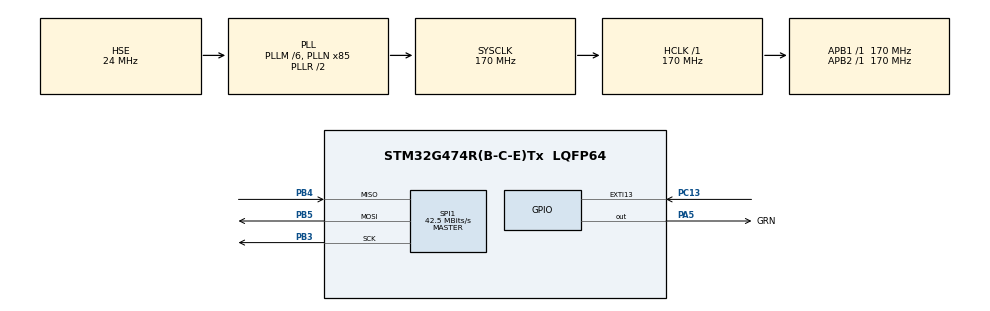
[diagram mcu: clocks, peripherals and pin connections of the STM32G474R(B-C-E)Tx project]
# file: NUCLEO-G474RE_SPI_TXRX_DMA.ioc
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Dma.Request0=SPI1_TX
Dma.Request1=SPI1_RX
Dma.SPI1_RX.1.Direction=DMA_PERIPH_TO_MEMORY
Dma.SPI1_RX.1.EventEnable=DISABLE
Dma.SPI1_RX.1.Instance=DMA1_Channel2
Dma.SPI1_RX.1.MemDataAlignment=DMA_MDATAALIGN_HALFWORD
Dma.SPI1_RX.1.MemInc=DMA_MINC_ENABLE
Dma.SPI1_RX.1.Mode=DMA_NORMAL
Dma.SPI1_RX.1.PeriphDataAlignment=DMA_PDATAALIGN_HALFWORD
Dma.SPI1_RX.1.PeriphInc=DMA_PINC_DISABLE
Dma.SPI1_RX.1.Polarity=HAL_DMAMUX_REQ_GEN_RISING
Dma.SPI1_RX.1.Priority=DMA_PRIORITY_HIGH
Dma.SPI1_RX.1.RequestNumber=1
Dma.SPI1_RX.1.SignalID=NONE
Dma.SPI1_RX.1.SyncEnable=DISABLE
Dma.SPI1_RX.1.SyncPolarity=HAL_DMAMUX_SYNC_NO_EVENT
Dma.SPI1_RX.1.SyncRequestNumber=1
Dma.SPI1_RX.1.SyncSignalID=NONE
Dma.SPI1_TX.0.Direction=DMA_MEMORY_TO_PERIPH
Dma.SPI1_TX.0.EventEnable=DISABLE
Dma.SPI1_TX.0.Instance=DMA1_Channel3
Dma.SPI1_TX.0.MemDataAlignment=DMA_MDATAALIGN_HALFWORD
Dma.SPI1_TX.0.MemInc=DMA_MINC_ENABLE
Dma.SPI1_TX.0.Mode=DMA_NORMAL
Dma.SPI1_TX.0.PeriphDataAlignment=DMA_PDATAALIGN_HALFWORD
Dma.SPI1_TX.0.PeriphInc=DMA_PINC_DISABLE
Dma.SPI1_TX.0.Polarity=HAL_DMAMUX_REQ_GEN_RISING
Dma.SPI1_TX.0.Priority=DMA_PRIORITY_LOW
Dma.SPI1_TX.0.RequestNumber=1
Dma.SPI1_TX.0.SignalID=NONE
Dma.SPI1_TX.0.SyncEnable=DISABLE
Dma.SPI1_TX.0.SyncPolarity=HAL_DMAMUX_SYNC_NO_EVENT
Dma.SPI1_TX.0.SyncRequestNumber=1
Dma.SPI1_TX.0.SyncSignalID=NONE
Mcu.Family=STM32G4
Mcu.Name=STM32G474R(B-C-E)Tx
Mcu.Package=LQFP64
NVIC.DMA1_Channel2_IRQn=true\:0\:0\:false\:false\:true\:true\:true
NVIC.DMA1_Channel3_IRQn=true\:0\:0\:false\:false\:true\:true\:true
NVIC.EXTI15_10_IRQn=true\:0\:0\:false\:false\:true\:true\:true
NVIC.PriorityGroup=NVIC_PRIORITYGROUP_4
PA13.Mode=Serial_Wire
PA13.Signal=SYS_JTMS-SWDIO
PA14.Mode=Serial_Wire
PA14.Signal=SYS_JTCK-SWCLK
PA5.GPIO_Label=GRN
PA5.Signal=GPIO_Output
PB3.GPIO_Speed=GPIO_SPEED_FREQ_VERY_HIGH
PB3.Mode=Full_Duplex_Master
PB3.Signal=SPI1_SCK
PB4.GPIO_Speed=GPIO_SPEED_FREQ_VERY_HIGH
PB4.Mode=Full_Duplex_Master
PB4.Signal=SPI1_MISO
PB5.GPIO_PuPd=GPIO_NOPULL
PB5.GPIO_Speed=GPIO_SPEED_FREQ_VERY_HIGH
PB5.Mode=Full_Duplex_Master
PB5.Signal=SPI1_MOSI
PC13.Signal=GPXTI13
PC14-OSC32_IN.Mode=LSE-External-Oscillator
PC14-OSC32_IN.Signal=RCC_OSC32_IN
PC15-OSC32_OUT.Mode=LSE-External-Oscillator
PC15-OSC32_OUT.Signal=RCC_OSC32_OUT
PF0-OSC_IN.Mode=HSE-External-Oscillator
PF0-OSC_IN.Signal=RCC_OSC_IN
PF1-OSC_OUT.Mode=HSE-External-Oscillator
PF1-OSC_OUT.Signal=RCC_OSC_OUT
ProjectManager.HeapSize=0x200
ProjectManager.StackSize=0x400
ProjectManager.TargetToolchain=STM32CubeIDE
RCC.ADC12Freq_Value=170000000
RCC.ADC345Freq_Value=170000000
RCC.AHBFreq_Value=170000000
RCC.APB1Freq_Value=170000000
RCC.APB1TimFreq_Value=170000000
RCC.APB2Freq_Value=170000000
RCC.APB2TimFreq_Value=170000000
RCC.CortexFreq_Value=170000000
RCC.EXTERNAL_CLOCK_VALUE=12288000
RCC.HCLKFreq_Value=170000000
RCC.HSE_VALUE=24000000
RCC.HSI48_VALUE=48000000
RCC.HSI_VALUE=16000000
RCC.PLLM=RCC_PLLM_DIV6
RCC.PLLN=85
RCC.PLLSourceVirtual=RCC_PLLSOURCE_HSE
RCC.SYSCLKFreq_VALUE=170000000
RCC.SYSCLKSource=RCC_SYSCLKSOURCE_PLLCLK
RCC.USBFreq_Value=170000000
RCC.VCOOutputFreq_Value=340000000
SPI1.BaudRatePrescaler=SPI_BAUDRATEPRESCALER_4
SPI1.CLKPhase=SPI_PHASE_1EDGE
SPI1.CLKPolarity=SPI_POLARITY_LOW
SPI1.CRCCalculation=SPI_CRCCALCULATION_DISABLE
SPI1.CalculateBaudRate=42.5 MBits/s
SPI1.DataSize=SPI_DATASIZE_16BIT
SPI1.Direction=SPI_DIRECTION_2LINES
SPI1.FirstBit=SPI_FIRSTBIT_MSB
SPI1.Mode=SPI_MODE_MASTER
SPI1.NSS=SPI_NSS_SOFT
SPI1.NSSPMode=SPI_NSS_PULSE_DISABLE
SPI1.TIMode=SPI_TIMODE_DISABLE
SPI1.VirtualType=VM_MASTER
VP_SYS_VS_DBSignals.Mode=DisableDeadBatterySignals
board=custom

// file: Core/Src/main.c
/* USER CODE BEGIN Header */
/**
  ******************************************************************************
  * @file    SPI/SPI_FullDuplex_ComDMA_Master/Src/main.c
  * @author  MCD Application Team
  * @brief   This sample code shows how to use STM32G4xx SPI HAL API to transmit
  *          and receive a data buffer with a communication process based on
  *          DMA transfer.
  *          The communication is done using 2 Boards.
  ******************************************************************************
  * @attention
  *
  * <h2><center>&copy; Copyright (c) 2019 STMicroelectronics.
  * All rights reserved.</center></h2>
  *
  * This software component is licensed by ST under BSD 3-Clause license,
  * the "License"; You may not use this file except in compliance with the
  * License. You may obtain a copy of the License at:
  *                        opensource.org/licenses/BSD-3-Clause
  *
  ******************************************************************************
  */
/* USER CODE END Header */

#include "main.h"

/* USER CODE BEGIN PD */
enum
{
  TRANSFER_WAIT,
  TRANSFER_COMPLETE,
  TRANSFER_ERROR
};

#define TXRX_SIZE 30000

/* USER CODE END PD */

SPI_HandleTypeDef hspi1;
DMA_HandleTypeDef hdma_spi1_tx;
DMA_HandleTypeDef hdma_spi1_rx;

/* USER CODE BEGIN PV */
/* Buffer used for transmission */
//uint8_t aTxBuffer[] = "****SPI - Two Boards communication based on DMA **** SPI Message ******** SPI Message ******** SPI Message ****";
uint16_t aTxBuffer[TXRX_SIZE];
uint8_t BLU_BUTTON = 0;

/* Buffer used for reception */
uint16_t aRxBuffer[TXRX_SIZE];

/* transfer state */
__IO uint32_t wTransferState = TRANSFER_WAIT;

/* USER CODE END PV */

void SystemClock_Config(void);
static void MX_GPIO_Init(void);
static void MX_DMA_Init(void);
static void MX_SPI1_Init(void);
/* USER CODE BEGIN PFP */
static uint16_t Buffercmp(uint16_t *pBuffer1, uint16_t *pBuffer2, uint16_t BufferLength);
/* USER CODE END PFP */

int main(void)
{
  /* USER CODE BEGIN 1 */

  /* STM32G4xx HAL library initialization:
       - Configure the Flash prefetch
       - Systick timer is configured by default as source of time base, but user
         can eventually implement his proper time base source (a general purpose
         timer for example or other time source), keeping in mind that Time base
         duration should be kept 1ms since PPP_TIMEOUT_VALUEs are defined and
         handled in milliseconds basis.
       - Set NVIC Group Priority to 4
       - Low Level Initialization
     */
  /* USER CODE END 1 */

  /* MCU Configuration--------------------------------------------------------*/

  /* Reset of all peripherals, Initializes the Flash interface and the Systick. */
  HAL_Init();

  /* Configure the system clock */
  SystemClock_Config();

  /* Initialize all configured peripherals */
  MX_GPIO_Init();
  MX_DMA_Init();
  MX_SPI1_Init();
  /* USER CODE BEGIN 2 */

  /* Configure LED2 */
  //BSP_LED_Init(LED2);

  /* Configure User push-button button */
  //BSP_PB_Init(BUTTON_USER, BUTTON_MODE_GPIO);
  /* Wait for User push-button press before starting the Communication */
  while (!BLU_BUTTON)
  {
	  HAL_GPIO_TogglePin(GPIOA, GRN_Pin);
	  HAL_Delay(100);
  }
  HAL_GPIO_WritePin(GPIOA, GRN_Pin, RESET);

  for(uint16_t cntr = 0; cntr < TXRX_SIZE; cntr++)
  {
	  aTxBuffer[cntr] = cntr;
  }
  aTxBuffer[0] = 0xF0A1;
  aTxBuffer[TXRX_SIZE - 1] = 0xF0A1;

  GPIOA->BSRR = (1<<6); // SET
  /*##-1- Start the Full Duplex Communication process ########################*/
  /* While the SPI in TransmitReceive process, user can transmit data through
     "aTxBuffer" buffer & receive data through "aRxBuffer" */
  if (HAL_SPI_TransmitReceive_DMA(&hspi1, (uint8_t *)aTxBuffer, (uint8_t *)aRxBuffer, TXRX_SIZE) != HAL_OK)
  {
    /* Transfer error in transmission process */
    Error_Handler();
  }

  /*##-2- Wait for the end of the transfer ###################################*/
  /*  Before starting a new communication transfer, you must wait the callback call
      to get the transfer complete confirmation or an error detection.
      For simplicity reasons, this example is just waiting till the end of the
      transfer, but application may perform other tasks while transfer operation
      is ongoing. */
  while (wTransferState == TRANSFER_WAIT)
  {
  }

  switch (wTransferState)
  {
  case TRANSFER_COMPLETE :
	  /*##-3- Compare the sent and received buffers ##############################*/
	  if (Buffercmp((uint16_t *)aTxBuffer, (uint16_t *)aRxBuffer, TXRX_SIZE))
	  {
		  /* Processing Error */
		  wTransferState = 2;
		  Error_Handler();
	  }
	  break;
  default :
	  wTransferState = 3;
	  Error_Handler();

	  break;
  }

  /* USER CODE END 2 */

  /* Infinite loop */
  while (1)
  {

  }
}

void SystemClock_Config(void)
{
  RCC_OscInitTypeDef RCC_OscInitStruct = {0};
  RCC_ClkInitTypeDef RCC_ClkInitStruct = {0};

  /** Configure the main internal regulator output voltage
  */
  HAL_PWREx_ControlVoltageScaling(PWR_REGULATOR_VOLTAGE_SCALE1_BOOST);
  /** Initializes the CPU, AHB and APB busses clocks
  */
  RCC_OscInitStruct.OscillatorType = RCC_OSCILLATORTYPE_HSE;
  RCC_OscInitStruct.HSEState = RCC_HSE_ON;
  RCC_OscInitStruct.PLL.PLLState = RCC_PLL_ON;
  RCC_OscInitStruct.PLL.PLLSource = RCC_PLLSOURCE_HSE;
  RCC_OscInitStruct.PLL.PLLM = RCC_PLLM_DIV6;
  RCC_OscInitStruct.PLL.PLLN = 85;
  RCC_OscInitStruct.PLL.PLLP = RCC_PLLP_DIV2;
  RCC_OscInitStruct.PLL.PLLQ = RCC_PLLQ_DIV2;
  RCC_OscInitStruct.PLL.PLLR = RCC_PLLR_DIV2;
  if (HAL_RCC_OscConfig(&RCC_OscInitStruct) != HAL_OK)
  {
    Error_Handler();
  }
  /** Initializes the CPU, AHB and APB busses clocks
  */
  RCC_ClkInitStruct.ClockType = RCC_CLOCKTYPE_HCLK|RCC_CLOCKTYPE_SYSCLK
                              |RCC_CLOCKTYPE_PCLK1|RCC_CLOCKTYPE_PCLK2;
  RCC_ClkInitStruct.SYSCLKSource = RCC_SYSCLKSOURCE_PLLCLK;
  RCC_ClkInitStruct.AHBCLKDivider = RCC_SYSCLK_DIV1;
  RCC_ClkInitStruct.APB1CLKDivider = RCC_HCLK_DIV1;
  RCC_ClkInitStruct.APB2CLKDivider = RCC_HCLK_DIV1;

  if (HAL_RCC_ClockConfig(&RCC_ClkInitStruct, FLASH_LATENCY_8) != HAL_OK)
  {
    Error_Handler();
  }
}

static void MX_SPI1_Init(void)
{

  /* SPI1 parameter configuration*/
  hspi1.Instance = SPI1;
  hspi1.Init.Mode = SPI_MODE_MASTER;
  hspi1.Init.Direction = SPI_DIRECTION_2LINES;
  hspi1.Init.DataSize = SPI_DATASIZE_16BIT;
  hspi1.Init.CLKPolarity = SPI_POLARITY_LOW;
  hspi1.Init.CLKPhase = SPI_PHASE_1EDGE;
  hspi1.Init.NSS = SPI_NSS_SOFT;
  hspi1.Init.BaudRatePrescaler = SPI_BAUDRATEPRESCALER_4;
  hspi1.Init.FirstBit = SPI_FIRSTBIT_MSB;
  hspi1.Init.TIMode = SPI_TIMODE_DISABLE;
  hspi1.Init.CRCCalculation = SPI_CRCCALCULATION_DISABLE;
  hspi1.Init.CRCPolynomial = 7;
  hspi1.Init.CRCLength = SPI_CRC_LENGTH_DATASIZE;
  hspi1.Init.NSSPMode = SPI_NSS_PULSE_DISABLE;
  if (HAL_SPI_Init(&hspi1) != HAL_OK)
  {
    Error_Handler();
  }

}

static void MX_DMA_Init(void)
{

  /* DMA controller clock enable */
  __HAL_RCC_DMAMUX1_CLK_ENABLE();
  __HAL_RCC_DMA1_CLK_ENABLE();

  /* DMA interrupt init */
  /* DMA1_Channel2_IRQn interrupt configuration */
  HAL_NVIC_SetPriority(DMA1_Channel2_IRQn, 0, 0);
  HAL_NVIC_EnableIRQ(DMA1_Channel2_IRQn);
  /* DMA1_Channel3_IRQn interrupt configuration */
  HAL_NVIC_SetPriority(DMA1_Channel3_IRQn, 0, 0);
  HAL_NVIC_EnableIRQ(DMA1_Channel3_IRQn);

}

static void MX_GPIO_Init(void)
{
  GPIO_InitTypeDef GPIO_InitStruct = {0};

  /* GPIO Ports Clock Enable */
  __HAL_RCC_GPIOC_CLK_ENABLE();
  __HAL_RCC_GPIOF_CLK_ENABLE();
  __HAL_RCC_GPIOA_CLK_ENABLE();
  __HAL_RCC_GPIOB_CLK_ENABLE();

  /*Configure GPIO pin Output Level */
  HAL_GPIO_WritePin(GPIOA, GRN_Pin|GPIO_PIN_6, GPIO_PIN_RESET);

  /*Configure GPIO pin : PC13 */
  GPIO_InitStruct.Pin = GPIO_PIN_13;
  GPIO_InitStruct.Mode = GPIO_MODE_IT_RISING;
  GPIO_InitStruct.Pull = GPIO_NOPULL;
  HAL_GPIO_Init(GPIOC, &GPIO_InitStruct);

  /*Configure GPIO pin : GRN_Pin */
  GPIO_InitStruct.Pin = GRN_Pin;
  GPIO_InitStruct.Mode = GPIO_MODE_OUTPUT_PP;
  GPIO_InitStruct.Pull = GPIO_NOPULL;
  GPIO_InitStruct.Speed = GPIO_SPEED_FREQ_LOW;
  HAL_GPIO_Init(GRN_GPIO_Port, &GPIO_InitStruct);

  /*Configure GPIO pin : PA6 */
  GPIO_InitStruct.Pin = GPIO_PIN_6;
  GPIO_InitStruct.Mode = GPIO_MODE_OUTPUT_PP;
  GPIO_InitStruct.Pull = GPIO_NOPULL;
  GPIO_InitStruct.Speed = GPIO_SPEED_FREQ_HIGH;
  HAL_GPIO_Init(GPIOA, &GPIO_InitStruct);

  /* EXTI interrupt init*/
  HAL_NVIC_SetPriority(EXTI15_10_IRQn, 0, 0);
  HAL_NVIC_EnableIRQ(EXTI15_10_IRQn);

}

/* USER CODE BEGIN 4 */
/**
  * @brief  TxRx Transfer completed callback.
  * @param  hspi: SPI handle
  * @note   This example shows a simple way to report end of DMA TxRx transfer, and
  *         you can add your own implementation.
  * @retval None
  */
void HAL_SPI_TxRxCpltCallback(SPI_HandleTypeDef *hspi)
{
  /* Turn LED2 on: Transfer in transmission/reception process is complete */
	GPIOA->BSRR = (1<<22);
	HAL_GPIO_WritePin(GPIOA, GRN_Pin, SET);
	wTransferState = TRANSFER_COMPLETE;
}

/**
  * @brief  SPI error callbacks.
  * @param  hspi: SPI handle
  * @note   This example shows a simple way to report transfer error, and you can
  *         add your own implementation.
  * @retval None
  */
void HAL_SPI_ErrorCallback(SPI_HandleTypeDef *hspi)
{
  wTransferState = TRANSFER_ERROR;
}

/**
  * @brief  Compares two buffers.
  * @param  pBuffer1, pBuffer2: buffers to be compared.
  * @param  BufferLength: buffer's length
  * @retval 0  : pBuffer1 identical to pBuffer2
  *         >0 : pBuffer1 differs from pBuffer2
  */
static uint16_t Buffercmp(uint16_t *pBuffer1, uint16_t *pBuffer2, uint16_t BufferLength)
{
  while (BufferLength--)
  {
    if ((*pBuffer1) != *pBuffer2)
    {
      return BufferLength;
    }
    pBuffer1++;
    pBuffer2++;
  }

  return 0;
}

/* USER CODE END 4 */

void Error_Handler(void)
{
  /* USER CODE BEGIN Error_Handler_Debug */
  /* User can add his own implementation to report the HAL error return state */
	HAL_GPIO_WritePin(GPIOA, GRN_Pin, RESET);
  while (1)
  {
    /* Toggle LED2 for error */
	  HAL_GPIO_TogglePin(GPIOA, GRN_Pin);
    HAL_Delay(1000);
  }
  /* USER CODE END Error_Handler_Debug */
}

/************************ (C) COPYRIGHT STMicroelectronics *****END OF FILE****/
